# K1921VK028 register map
Vendor: NIIET; Series: K1921VKx; File version: 2.17
CPU: CM4 r0p1, little endian, MPU, FPU, 4 interrupt priority bits
Registers are 32-bit, read-write, reset 0x0 unless marked. A register's access mark holds for its fields unless they carry their own. Offsets are from the block's base; [hi:lo] are bit positions; {n}, {i} and the like mark numbered series; 'fields as' and 'values as' point back to an identical list.

## UART0 — UART control registers
Base 0x40085000
Same registers: UART1 0x40086000, UART2 0x40087000, UART3 0x40088000
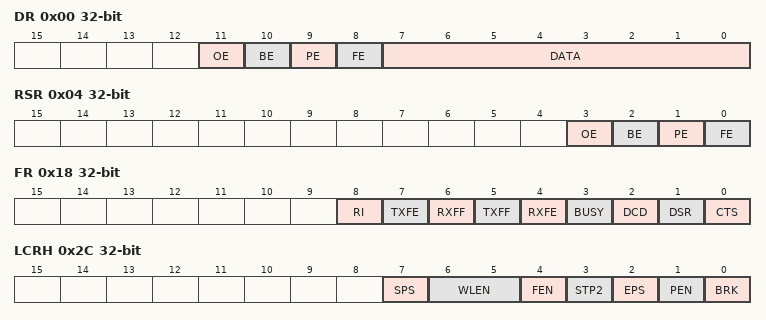
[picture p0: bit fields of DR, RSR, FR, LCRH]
0x00 DR — Data Register
  [11] OE ro — Overrun error
  [10] BE ro — Break error
  [9] PE ro — Parity error
  [8] FE ro — Framing error
  [7:0] DATA
0x04 RSR — Receive Status Register/Error Clear Register
  [3] OE — Overrun error
  [2] BE — Break error
  [1] PE — Parity error
  [0] FE — Framing error
0x18 FR ro — Flag Register
  [8] RI — Ring indicator
  [7] TXFE — Transmit FIFO empty
  [6] RXFF — Receive FIFO full
  [5] TXFF — Transmit FIFO full
  [4] RXFE — Receive FIFO empty
  [3] BUSY — UART busy
  [2] DCD — Data carrier detect
  [1] DSR — Data set ready
  [0] CTS — Clear to send
0x20 ILPR — IrDA Low-Power Counter Register
  [7:0] ILPDVSR
0x24 IBRD — Integer Baud Rate Register
  [15:0] DIVINT
0x28 FBRD — Fractional Baud Rate Register
  [5:0] DIVFRAC
0x2C LCRH — Line Control Register
  [7] SPS — Stick parity select
  [6:5] WLEN
    {v}={v+5} bit in informational word (v=0..3)
  [4] FEN — Enable FIFOs
  [3] STP2 — Two stop bits select
  [2] EPS — Even parity select
  [1] PEN — Parity enable
  [0] BRK — Send break
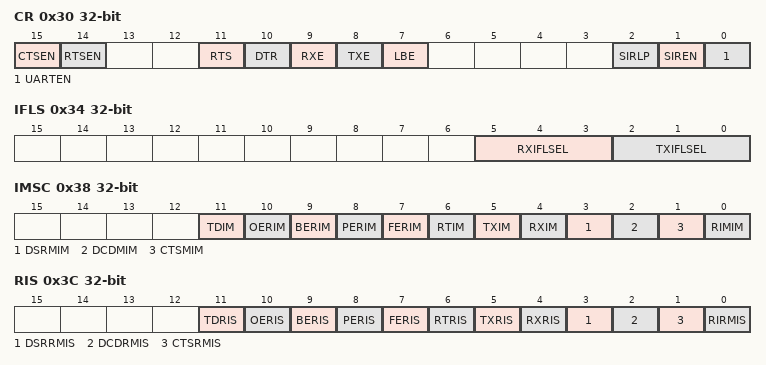
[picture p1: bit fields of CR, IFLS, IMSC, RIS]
0x30 CR — Control Register
  [15] CTSEN — CTS hardware flow control enable
  [14] RTSEN — RTS hardware flow control enable
  [11] RTS — Request to send
  [10] DTR — Data transmit ready
  [9] RXE — Receive enable
  [8] TXE — Transmit enable
  [7] LBE — Loopback enable
  [2] SIRLP — Enable SIR low-power IrDA mode
  [1] SIREN — Enable IrDA SIR ENDEC
  [0] UARTEN — UART enable
0x34 IFLS — Interrupt FIFO Level Select Register
  [5:3] RXIFLSEL
    0=Lvl18 (interrupt on 1/8); 1=Lvl14 (interrupt on 1/4); 2=Lvl12 (interrupt on 1/2); 3=Lvl34 (interrupt on 3/4); 4=Lvl78 (interrupt on 7/8)
  [2:0] TXIFLSEL
    values as RXIFLSEL
0x38 IMSC — Interrupt Mask Set/Clear Register
  [11] TDIM — Transmit done interrupt mask
  [10] OERIM — Overrun error interrupt mask
  [9] BERIM — Break error interrupt mask
  [8] PERIM — Parity error interrupt mask
  [7] FERIM — Framing error interrupt mask
  [6] RTIM — Receive timeout interrupt mask
  [5] TXIM — Transmit interrupt mask
  [4] RXIM — Receive interrupt mask
  [3] DSRMIM — nUARTDSR modem interrupt mask
  [2] DCDMIM — nUARTDCD modem interrupt mask
  [1] CTSMIM — nUARTCTS modem interrupt mask
  [0] RIMIM — nUARTRI modem interrupt mask
0x3C RIS ro — Raw Interrupt Status Register
  [11] TDRIS — Transmit done raw interrupt status
  [10] OERIS — Overrun error interrupt status
  [9] BERIS — Break error interrupt status
  [8] PERIS — Parity error interrupt status
  [7] FERIS — Framing error interrupt status
  [6] RTRIS — Receive timeout interrupt status
  [5] TXRIS — Transmit interrupt status
  [4] RXRIS — Receive interrupt status
  [3] DSRRMIS — nUARTDSR modem interrupt status
  [2] DCDRMIS — nUARTDCD modem interrupt status
  [1] CTSRMIS — nUARTCTS modem interrupt status
  [0] RIRMIS — nUARTRI modem interrupt status
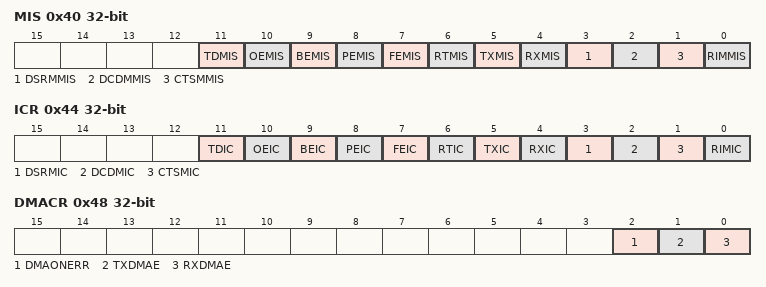
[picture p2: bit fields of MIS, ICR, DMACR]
0x40 MIS ro — Masked Interrupt Status Register
  [11] TDMIS — Transmit done masked interrupt status
  [10] OEMIS — Overrun error masked interrupt status
  [9] BEMIS — Break error masked interrupt status
  [8] PEMIS — Parity error masked interrupt status
  [7] FEMIS — Framing error masked interrupt status
  [6] RTMIS — Receive timeout masked interrupt status
  [5] TXMIS — Transmit masked interrupt status
  [4] RXMIS — Receive masked interrupt status
  [3] DSRMMIS — nUARTDSR modem masked interrupt status
  [2] DCDMMIS — nUARTDCD modem masked interrupt status
  [1] CTSMMIS — nUARTCTS modem masked interrupt status
  [0] RIMMIS — nUARTRI modem masked interrupt status
0x44 ICR wo — Interrupt Clear Register
  [11] TDIC — Transmit done interrupt clear
  [10] OEIC — Overrun error interrupt clear
  [9] BEIC — Break error interrupt clear
  [8] PEIC — Parity error interrupt clear
  [7] FEIC — Framing error interrupt clear
  [6] RTIC — Receive timeout interrupt clear
  [5] TXIC — Transmit interrupt clear
  [4] RXIC — Receive interrupt clear
  [3] DSRMIC — nUARTDSR modem interrupt clear
  [2] DCDMIC — nUARTDCD modem interrupt clear
  [1] CTSMIC — nUARTCTS modem interrupt clear
  [0] RIMIC — nUARTRI modem interrupt clear
0x48 DMACR — DMA Control Register
  [2] DMAONERR — DMA on error
  [1] TXDMAE — Transmit DMA enable
  [0] RXDMAE — Receive DMA enable
